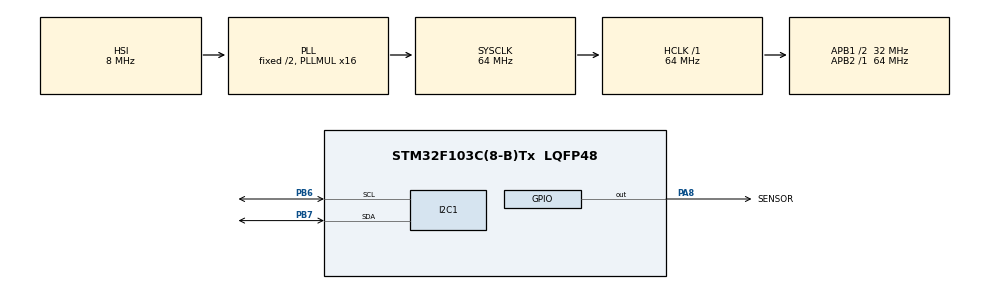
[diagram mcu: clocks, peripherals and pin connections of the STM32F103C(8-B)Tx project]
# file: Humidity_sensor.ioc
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I2C1.I2C_Mode=I2C_Fast
Mcu.Family=STM32F1
Mcu.Name=STM32F103C(8-B)Tx
Mcu.Package=LQFP48
NVIC.PriorityGroup=NVIC_PRIORITYGROUP_4
PA13.Mode=Serial_Wire
PA13.Signal=SYS_JTMS-SWDIO
PA14.Mode=Serial_Wire
PA14.Signal=SYS_JTCK-SWCLK
PA8.GPIO_Label=SENSOR
PA8.GPIO_PuPd=GPIO_PULLUP
PA8.PinState=GPIO_PIN_SET
PA8.Signal=GPIO_Output
PB6.Mode=I2C
PB6.Signal=I2C1_SCL
PB7.Mode=I2C
PB7.Signal=I2C1_SDA
PD0-OSC_IN.Mode=HSE-External-Oscillator
PD0-OSC_IN.Signal=RCC_OSC_IN
PD1-OSC_OUT.Mode=HSE-External-Oscillator
PD1-OSC_OUT.Signal=RCC_OSC_OUT
ProjectManager.HeapSize=0x200
ProjectManager.StackSize=0x400
ProjectManager.TargetToolchain=STM32CubeIDE
RCC.AHBFreq_Value=64000000
RCC.APB1CLKDivider=RCC_HCLK_DIV2
RCC.APB1Freq_Value=32000000
RCC.APB1TimFreq_Value=64000000
RCC.APB2Freq_Value=64000000
RCC.APB2TimFreq_Value=64000000
RCC.HCLKFreq_Value=64000000
RCC.HSE_VALUE=16000000
RCC.PLLMUL=RCC_PLL_MUL16
RCC.SYSCLKFreq_VALUE=64000000
RCC.SYSCLKSource=RCC_SYSCLKSOURCE_PLLCLK
RCC.USBFreq_Value=64000000
TIM1.Prescaler=63
VP_TIM1_VS_ClockSourceINT.Mode=Internal
board=custom

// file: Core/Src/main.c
/* USER CODE BEGIN Header */
/**
  ******************************************************************************
  * @file           : main.c
  * @brief          : Main program body
  ******************************************************************************
  * @attention
  *
  * Copyright (c) 2025 STMicroelectronics.
  * All rights reserved.
  *
  * This software is licensed under terms that can be found in the LICENSE file
  * in the root directory of this software component.
  * If no LICENSE file comes with this software, it is provided AS-IS.
  *
  ******************************************************************************
  */
/* USER CODE END Header */
#include "main.h"
#include "i2c.h"
#include "tim.h"
#include "gpio.h"

/* USER CODE BEGIN Includes */
#include"fonts.h"
#include"SH1106.h"
#include"bitmap.h"
/* USER CODE END Includes */

void SystemClock_Config(void);

/* USER CODE BEGIN 0 */

/*******************************DHT22 FUNCTIONS *****************************************/
uint8_t Rh_byte1, Rh_byte2, Tmp_byte1, Tmp_byte2;
uint16_t Sum, Rh, Tmp;
float Temperature = 0;
float Humidity = 0;
uint8_t Presence = 0;
char str[20];

void display_view(){
	SH1106_Fill(SH1106_COLOR_BLACK);
	SH1106_DrawRectangle(20, 5, 100, 12,SH1106_COLOR_WHITE);
	SH1106_GotoXY(30, 7);
	SH1106_Puts("TEMPERATURA", &Font_7x10, SH1106_COLOR_WHITE);
	SH1106_DrawFilledRectangle(45,19, 50, 20, 1);
	SH1106_GotoXY(46, 20);
	sprintf(str, "%.1f%cC", Temperature, 127);

	SH1106_Puts(str, &Font_7x10, SH1106_COLOR_BLACK);
	SH1106_UpdateScreen();
}
void Set_Pin_Output(GPIO_TypeDef *GPIOx, uint16_t GPIO_Pin){
	GPIO_InitTypeDef GPIO_InitStruct = {0};
	GPIO_InitStruct.Pin = GPIO_Pin;
	GPIO_InitStruct.Mode = GPIO_MODE_OUTPUT_PP;
	GPIO_InitStruct.Speed = GPIO_SPEED_FREQ_LOW;
	HAL_GPIO_Init(GPIOx, &GPIO_InitStruct);
}
void Set_Pin_Input(GPIO_TypeDef *GPIOx, uint16_t GPIO_Pin){
	GPIO_InitTypeDef GPIO_InitStruct = {0};
	GPIO_InitStruct.Pin = GPIO_Pin;
	GPIO_InitStruct.Mode = GPIO_MODE_INPUT;
	GPIO_InitStruct.Pull = GPIO_PULLUP;
	HAL_GPIO_Init(GPIOx, &GPIO_InitStruct);
}
void delay(uint16_t time){
	__HAL_TIM_SET_COUNTER(&htim1, 0);
	while(__HAL_TIM_GET_COUNTER(&htim1)< time);
}

void DHT22_Start(){
	Set_Pin_Output(SENSOR_GPIO_Port, SENSOR_Pin);
	HAL_GPIO_WritePin(SENSOR_GPIO_Port, SENSOR_Pin, 0);
	HAL_Delay(18);

	HAL_GPIO_WritePin(SENSOR_GPIO_Port, SENSOR_Pin, 1);
	delay(40);
	Set_Pin_Input(SENSOR_GPIO_Port, SENSOR_Pin);
}
uint8_t DHT22_Check_Response()
{
	Set_Pin_Input(SENSOR_GPIO_Port, SENSOR_Pin);
	uint8_t Response = 0;
	uint16_t timeout = 0;
	delay(40);
	if (!(HAL_GPIO_ReadPin (SENSOR_GPIO_Port, SENSOR_Pin)))
	{
		delay (80);

		if ((HAL_GPIO_ReadPin (SENSOR_GPIO_Port, SENSOR_Pin))) Response = 1;
		else Response = -1;
	}

	timeout = 0;
	    while ((HAL_GPIO_ReadPin(SENSOR_GPIO_Port, SENSOR_Pin)) && timeout < 500) {
	        timeout++;
	        delay(1);
	    }

	    if (timeout >= 500) return 0;
	    return Response;
}
uint8_t DHT22_Read()
{
	uint8_t i,j;
	for (j=0;j<8;j++)
	{
		while (!(HAL_GPIO_ReadPin (SENSOR_GPIO_Port, SENSOR_Pin)));
		delay (40);   // wait for 40 us

		if (!(HAL_GPIO_ReadPin (SENSOR_GPIO_Port, SENSOR_Pin)))
		{
			i&= ~(1<<(7-j));   // write 0
		}
		else i|= (1<<(7-j));  // if the pin is high, write 1
		while ((HAL_GPIO_ReadPin (SENSOR_GPIO_Port, SENSOR_Pin)));  // wait for the pin to go low
	}

	return i;
}
/* USER CODE END 0 */

int main(void)
{

  /* MCU Configuration--------------------------------------------------------*/

  /* Reset of all peripherals, Initializes the Flash interface and the Systick. */
  HAL_Init();

  /* Configure the system clock */
  SystemClock_Config();

  /* Initialize all configured peripherals */
  MX_GPIO_Init();
  MX_I2C1_Init();
  MX_TIM1_Init();
  /* USER CODE BEGIN 2 */
  SH1106_Init();
  SH1106_UpdateScreen();
  HAL_TIM_Base_Start(&htim1);
  /* USER CODE END 2 */

  /* Infinite loop */
  /* USER CODE BEGIN WHILE */

  while (1)
  {
	  DHT22_Start();
	  Presence = DHT22_Check_Response();
	  Rh_byte1 = DHT22_Read ();
	  Rh_byte2 = DHT22_Read ();
	  Tmp_byte1 = DHT22_Read ();
	  Tmp_byte2 = DHT22_Read ();
	  Sum = DHT22_Read();
      Tmp = ((Tmp_byte1<<8)|Tmp_byte2);
      Rh = ((Rh_byte1<<8)|Rh_byte2);

      if (Tmp_byte1 & 0x80) {
          Temperature = (float)((Tmp & 0x7FFF) / 10.0) * -1.0;
      } else {
          Temperature = (float)(Tmp / 10.0);
      }
      Humidity = (float) (Rh/10.0);
      display_view();
      HAL_Delay(2000);

    /* USER CODE END WHILE */

  }
}

void SystemClock_Config(void)
{
  RCC_OscInitTypeDef RCC_OscInitStruct = {0};
  RCC_ClkInitTypeDef RCC_ClkInitStruct = {0};

  /** Initializes the RCC Oscillators according to the specified parameters
  * in the RCC_OscInitTypeDef structure.
  */
  RCC_OscInitStruct.OscillatorType = RCC_OSCILLATORTYPE_HSI;
  RCC_OscInitStruct.HSIState = RCC_HSI_ON;
  RCC_OscInitStruct.HSICalibrationValue = RCC_HSICALIBRATION_DEFAULT;
  RCC_OscInitStruct.PLL.PLLState = RCC_PLL_ON;
  RCC_OscInitStruct.PLL.PLLSource = RCC_PLLSOURCE_HSI_DIV2;
  RCC_OscInitStruct.PLL.PLLMUL = RCC_PLL_MUL16;
  if (HAL_RCC_OscConfig(&RCC_OscInitStruct) != HAL_OK)
  {
    Error_Handler();
  }

  /** Initializes the CPU, AHB and APB buses clocks
  */
  RCC_ClkInitStruct.ClockType = RCC_CLOCKTYPE_HCLK|RCC_CLOCKTYPE_SYSCLK
                              |RCC_CLOCKTYPE_PCLK1|RCC_CLOCKTYPE_PCLK2;
  RCC_ClkInitStruct.SYSCLKSource = RCC_SYSCLKSOURCE_PLLCLK;
  RCC_ClkInitStruct.AHBCLKDivider = RCC_SYSCLK_DIV1;
  RCC_ClkInitStruct.APB1CLKDivider = RCC_HCLK_DIV2;
  RCC_ClkInitStruct.APB2CLKDivider = RCC_HCLK_DIV1;

  if (HAL_RCC_ClockConfig(&RCC_ClkInitStruct, FLASH_LATENCY_2) != HAL_OK)
  {
    Error_Handler();
  }
}

void Error_Handler(void)
{
  __disable_irq();
  while (1)
  {
  }
}
